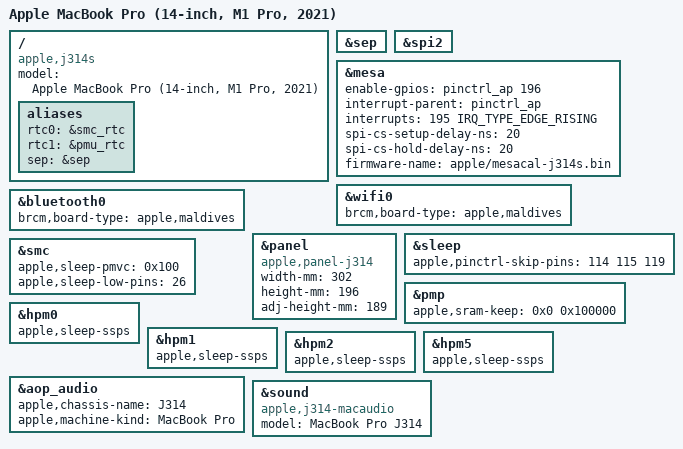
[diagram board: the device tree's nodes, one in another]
// SPDX-License-Identifier: GPL-2.0+ OR MIT
/*
 * MacBook Pro (14-inch, M1 Pro, 2021)
 *
 * target-type: J314s
 *
 * Copyright The Asahi Linux Contributors
 */

/dts-v1/;

/*
 * PMP manages system power states; with pmgr-misc leaving DCS to it and
 * lowering only the fabric for sleep, this board resumes from s2idle and
 * idles about 0.8 W lower.
 */
#define APPLE_USE_PMP

#include "t6000.dtsi"
#include "t600x-j314-j316.dtsi"
#include "t6000-hwmon-rails.dtsi"

/ {
	compatible = "apple,j314s", "apple,t6000", "apple,arm-platform";
	model = "Apple MacBook Pro (14-inch, M1 Pro, 2021)";

	aliases {
		rtc0 = &smc_rtc;
		rtc1 = &pmu_rtc;
		sep = &sep;
	};
};

/*
 * m1n1 keys off the sep alias to add the sepfw region and the boot
 * manifests the driver needs to cold-boot SEPOS.
 */
&sep {
	status = "okay";
};

/*
 * From the J314s platform device tree (/arm-io/spi2/mesa): the power line
 * is gpio0 pin 196 (function-mesa_pwr, active high) and the data-ready line
 * is pin 195, the same lines as J316s.
 */
&spi2 {
	status = "okay";
};

&mesa {
	status = "okay";
	enable-gpios = <&pinctrl_ap 196 GPIO_ACTIVE_HIGH>;
	interrupt-parent = <&pinctrl_ap>;
	interrupts = <195 IRQ_TYPE_EDGE_RISING>;
	spi-cs-setup-delay-ns = <20>;
	spi-cs-hold-delay-ns = <20>;
	/*
	 * Per-device factory data, extracted from this machine's own macOS
	 * install; it is not redistributable.
	 */
	firmware-name = "apple/mesacal-j314s.bin";
};

&wifi0 {
	brcm,board-type = "apple,maldives";
};

&bluetooth0 {
	brcm,board-type = "apple,maldives";
};

&panel {
	compatible = "apple,panel-j314", "apple,panel-mini-led", "apple,panel";
	width-mm = <302>;
	height-mm = <196>;
	adj-height-mm = <189>;
};

/*
 * Suspend-to-RAM, qualified on this board. What follows is what its sequence
 * needs from the other devices.
 */
&sleep {
	/*
	 * Left alone across a sleep, as in the board's ADT no-restore-gpio-pins.
	 */
	apple,pinctrl-skip-pins = <114 115 119>;
	status = "okay";
};

&smc {
	/* VDD_CIO rail mask before the sleep notice: no port's rail kept up */
	apple,sleep-pmvc = <0x100>;
	/* The SD card reader's power enable (port01's pwren), off while asleep */
	apple,sleep-low-pins = <26>;
};

&pmp {
	/* The sleep takes the firmware's SRAM: all of it is kept and written back */
	apple,sram-keep = <0x0 0x100000>;
};

/* macOS moves each port controller to S3 before the sleep and to S0 after it. */
&hpm0 {
	apple,sleep-ssps;
};

&hpm1 {
	apple,sleep-ssps;
};

&hpm2 {
	apple,sleep-ssps;
};

&hpm5 {
	apple,sleep-ssps;
};

&aop_audio {
	apple,chassis-name = "J314";
	apple,machine-kind = "MacBook Pro";
};

&sound {
	compatible = "apple,j314-macaudio", "apple,macaudio";
	model = "MacBook Pro J314";
};
